# ESP32 register map
Vendor: ESPRESSIF SYSTEMS (SHANGHAI) CO., LTD.; Series: ESP32 Series; File version: 17
CPU: Xtensa LX6 r0p0, little endian, no MPU, FPU, 0 interrupt priority bits
Address unit: 32 bits
Registers are 32-bit, read-write, reset 0x0 unless marked. A register's access mark holds for its fields unless they carry their own. Offsets are from the block's base; [hi:lo] are bit positions; {n}, {i} and the like mark numbered series.

## I2C0 — I2C (Inter-Integrated Circuit) Controller 0
Base 0x3FF53000
Same registers: I2C1 0x3FF67000
0x00 SCL_LOW_PERIOD
  [13:0] SCL_LOW_PERIOD — This register is used to configure the low level width of SCL clock.
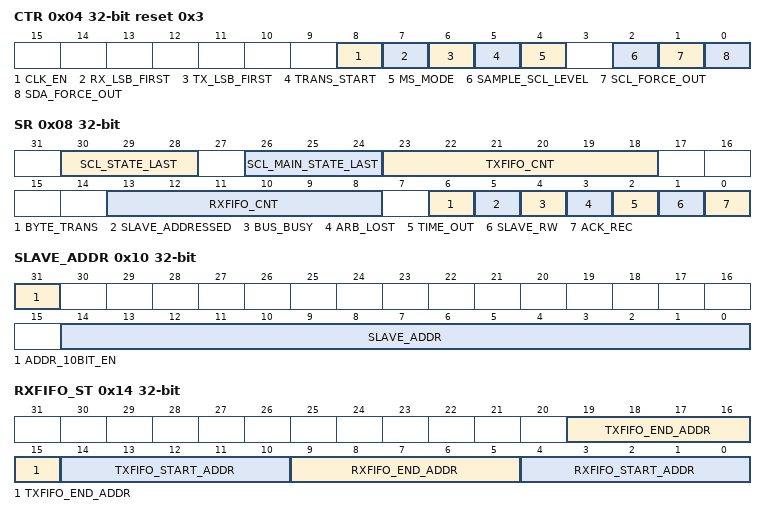
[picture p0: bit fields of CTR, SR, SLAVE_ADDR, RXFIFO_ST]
0x04 CTR reset 0x3
  [8] CLK_EN — This is the clock gating control bit for reading or writing registers.
  [7] RX_LSB_FIRST — This bit is used to control the storage mode for received datas. 1: receive data from most significant bit 0: receive data from least significant bit
  [6] TX_LSB_FIRST — This bit is used to control the sending mode for data need to be send. 1: receive data from most significant bit 0: receive data from least significant bit
  [5] TRANS_START — Set this bit to start sending data in txfifo.
  [4] MS_MODE — Set this bit to configure the module as i2c master clear this bit to configure the module as i2c slave.
  [2] SAMPLE_SCL_LEVEL — Set this bit to sample data in SCL low level. clear this bit to sample data in SCL high level.
  [1] SCL_FORCE_OUT — 1: normally ouput scl clock 0: exchange the function of scl_o and scl_oe (scl_o is the original internal output scl signal scl_oe is the enable bit for the internal output scl signal)
  [0] SDA_FORCE_OUT — 1: normally ouput sda data 0: exchange the function of sda_o and sda_oe (sda_o is the original internal output sda signal sda_oe is the enable bit for the internal output sda signal)
0x08 SR ro
  [30:28] SCL_STATE_LAST — This register stores the value of state machine to produce SCL. 3'h0: SCL_IDLE 3'h1:SCL_START 3'h2:SCL_LOW_EDGE 3'h3: SCL_LOW 3'h4:SCL_HIGH_EDGE 3'h5:SCL_HIGH 3'h6:SCL_STOP
  [26:24] SCL_MAIN_STATE_LAST — This register stores the value of state machine for i2c module. 3'h0: SCL_MAIN_IDLE 3'h1: SCL_ADDRESS_SHIFT 3'h2: SCL_ACK_ADDRESS 3'h3: SCL_RX_DATA 3'h4 SCL_TX_DATA 3'h5:SCL_SEND_ACK 3'h6:SCL_WAIT_ACK
  [23:18] TXFIFO_CNT — This register stores the amount of received data in ram.
  [13:8] RXFIFO_CNT — This register represent the amount of data need to send.
  [6] BYTE_TRANS — This register changes to high level when one byte is transferred.
  [5] SLAVE_ADDRESSED — when configured as i2c slave and the address send by master is equal to slave's address then this bit will be high level.
  [4] BUS_BUSY — 1:I2C bus is busy transferring data. 0:I2C bus is in idle state.
  [3] ARB_LOST — when I2C lost control of SDA line this register changes to high level.
  [2] TIME_OUT — when I2C takes more than time_out_reg clocks to receive a data then this register changes to high level.
  [1] SLAVE_RW — when in slave mode 1: master read slave 0: master write slave.
  [0] ACK_REC — This register stores the value of ACK bit.
0x0C TO
  [19:0] TIME_OUT — This register is used to configure the max clock number of receiving a data.
0x10 SLAVE_ADDR
  [31] ADDR_10BIT_EN — This register is used to enable slave 10bit address mode.
  [14:0] SLAVE_ADDR — when configured as i2c slave this register is used to configure slave's address.
0x14 RXFIFO_ST ro
  [19:15] TXFIFO_END_ADDR — This is the offset address of the last sending data as described in nonfifo_tx_thres register.
  [14:10] TXFIFO_START_ADDR — This is the offset address of the first sending data as described in nonfifo_tx_thres register.
  [9:5] RXFIFO_END_ADDR — This is the offset address of the first receiving data as described in nonfifo_rx_thres_register.
  [4:0] RXFIFO_START_ADDR — This is the offset address of the last receiving data as described in nonfifo_rx_thres_register.
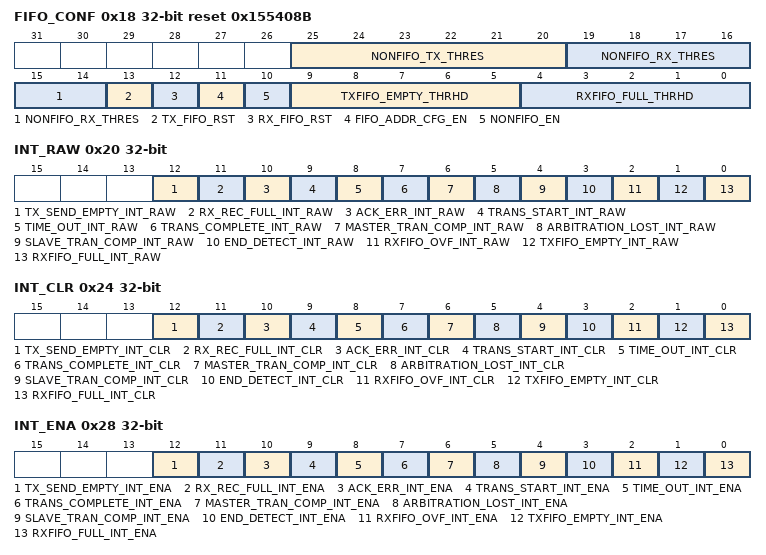
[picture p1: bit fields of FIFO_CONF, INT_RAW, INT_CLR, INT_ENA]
0x18 FIFO_CONF reset 0x155408B
  [25:20] NONFIFO_TX_THRES — when I2C sends more than nonfifo_tx_thres data it will produce tx_send_empty_int_raw interrupt and update the current offset address of the sending data.
  [19:14] NONFIFO_RX_THRES — when I2C receives more than nonfifo_rx_thres data it will produce rx_send_full_int_raw interrupt and update the current offset address of the receiving data.
  [13] TX_FIFO_RST — Set this bit to reset tx fifo when using apb fifo access.
  [12] RX_FIFO_RST — Set this bit to reset rx fifo when using apb fifo access.
  [11] FIFO_ADDR_CFG_EN — When this bit is set to 1 then the byte after address represent the offset address of I2C Slave's ram.
  [10] NONFIFO_EN — Set this bit to enble apb nonfifo access.
  [9:5] TXFIFO_EMPTY_THRHD — Config txfifo empty threhd value when using apb fifo access
  [4:0] RXFIFO_FULL_THRHD
0x1C DATA ro
  [7:0] FIFO_RDATA — The register represent the byte data read from rxfifo when use apb fifo access
0x20 INT_RAW ro
  [12] TX_SEND_EMPTY_INT_RAW — The raw interrupt status bit for tx_send_empty_int interrupt.when I2C sends more data than nonfifo_tx_thres it will produce tx_send_empty_int interrupt..
  [11] RX_REC_FULL_INT_RAW — The raw interrupt status bit for rx_rec_full_int interrupt. when I2C receives more data than nonfifo_rx_thres it will produce rx_rec_full_int interrupt.
  [10] ACK_ERR_INT_RAW — The raw interrupt status bit for ack_err_int interrupt. when I2C receives a wrong ACK bit it will produce ack_err_int interrupt..
  [9] TRANS_START_INT_RAW — The raw interrupt status bit for trans_start_int interrupt. when I2C sends the START bit it will produce trans_start_int interrupt.
  [8] TIME_OUT_INT_RAW — The raw interrupt status bit for time_out_int interrupt. when I2C takes a lot of time to receive a data it will produce time_out_int interrupt.
  [7] TRANS_COMPLETE_INT_RAW — The raw interrupt status bit for trans_complete_int interrupt. when I2C Master finished STOP command it will produce trans_complete_int interrupt.
  [6] MASTER_TRAN_COMP_INT_RAW — The raw interrupt status bit for master_tra_comp_int interrupt. when I2C Master sends or receives a byte it will produce master_tran_comp_int interrupt.
  [5] ARBITRATION_LOST_INT_RAW — The raw interrupt status bit for arbitration_lost_int interrupt.when I2C lost the usage right of I2C BUS it will produce arbitration_lost_int interrupt.
  [4] SLAVE_TRAN_COMP_INT_RAW — The raw interrupt status bit for slave_tran_comp_int interrupt. when I2C Slave detectsthe STOP bit it will produce slave_tran_comp_int interrupt.
  [3] END_DETECT_INT_RAW — The raw interrupt status bit for end_detect_int interrupt. when I2C deals with the END command it will produce end_detect_int interrupt.
  [2] RXFIFO_OVF_INT_RAW — The raw interrupt status bit for receiving data overflow when use apb fifo access.
  [1] TXFIFO_EMPTY_INT_RAW — The raw interrupt status bit for txfifo empty when use apb fifo access.
  [0] RXFIFO_FULL_INT_RAW — The raw interrupt status bit for rxfifo full when use apb fifo access.
0x24 INT_CLR wo
  [12] TX_SEND_EMPTY_INT_CLR — Set this bit to clear the tx_send_empty_int interrupt.
  [11] RX_REC_FULL_INT_CLR — Set this bit to clear the rx_rec_full_int interrupt.
  [10] ACK_ERR_INT_CLR — Set this bit to clear the ack_err_int interrupt.
  [9] TRANS_START_INT_CLR — Set this bit to clear the trans_start_int interrupt.
  [8] TIME_OUT_INT_CLR — Set this bit to clear the time_out_int interrupt.
  [7] TRANS_COMPLETE_INT_CLR — Set this bit to clear the trans_complete_int interrupt.
  [6] MASTER_TRAN_COMP_INT_CLR — Set this bit to clear the master_tran_comp interrupt.
  [5] ARBITRATION_LOST_INT_CLR — Set this bit to clear the arbitration_lost_int interrupt.
  [4] SLAVE_TRAN_COMP_INT_CLR — Set this bit to clear the slave_tran_comp_int interrupt.
  [3] END_DETECT_INT_CLR — Set this bit to clear the end_detect_int interrupt.
  [2] RXFIFO_OVF_INT_CLR — Set this bit to clear the rxfifo_ovf_int interrupt.
  [1] TXFIFO_EMPTY_INT_CLR — Set this bit to clear the txfifo_empty_int interrupt.
  [0] RXFIFO_FULL_INT_CLR — Set this bit to clear the rxfifo_full_int interrupt.
0x28 INT_ENA
  [12] TX_SEND_EMPTY_INT_ENA — The enable bit for tx_send_empty_int interrupt.
  [11] RX_REC_FULL_INT_ENA — The enable bit for rx_rec_full_int interrupt.
  [10] ACK_ERR_INT_ENA — The enable bit for ack_err_int interrupt.
  [9] TRANS_START_INT_ENA — The enable bit for trans_start_int interrupt.
  [8] TIME_OUT_INT_ENA — The enable bit for time_out_int interrupt.
  [7] TRANS_COMPLETE_INT_ENA — The enable bit for trans_complete_int interrupt.
  [6] MASTER_TRAN_COMP_INT_ENA — The enable bit for master_tran_comp_int interrupt.
  [5] ARBITRATION_LOST_INT_ENA — The enable bit for arbitration_lost_int interrupt.
  [4] SLAVE_TRAN_COMP_INT_ENA — The enable bit for slave_tran_comp_int interrupt.
  [3] END_DETECT_INT_ENA — The enable bit for end_detect_int interrupt.
  [2] RXFIFO_OVF_INT_ENA — The enable bit for rxfifo_ovf_int interrupt.
  [1] TXFIFO_EMPTY_INT_ENA — The enable bit for txfifo_empty_int interrupt.
  [0] RXFIFO_FULL_INT_ENA — The enable bit for rxfifo_full_int interrupt.
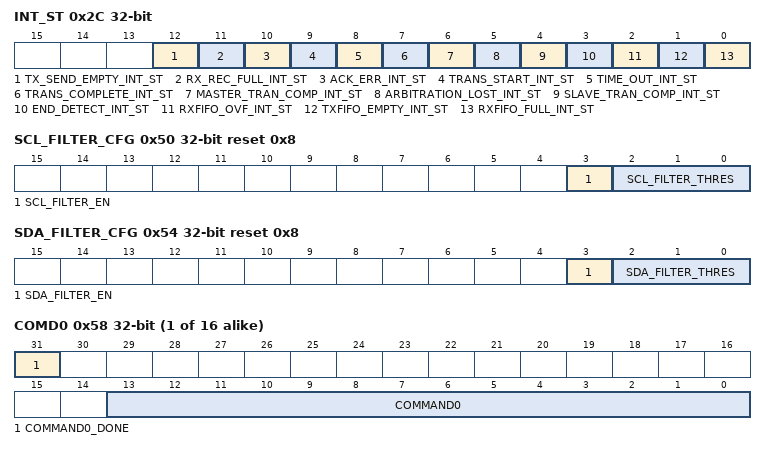
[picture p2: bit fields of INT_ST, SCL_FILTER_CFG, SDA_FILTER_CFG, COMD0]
0x2C INT_ST ro
  [12] TX_SEND_EMPTY_INT_ST — The masked interrupt status for tx_send_empty_int interrupt.
  [11] RX_REC_FULL_INT_ST — The masked interrupt status for rx_rec_full_int interrupt.
  [10] ACK_ERR_INT_ST — The masked interrupt status for ack_err_int interrupt.
  [9] TRANS_START_INT_ST — The masked interrupt status for trans_start_int interrupt.
  [8] TIME_OUT_INT_ST — The masked interrupt status for time_out_int interrupt.
  [7] TRANS_COMPLETE_INT_ST — The masked interrupt status for trans_complete_int interrupt.
  [6] MASTER_TRAN_COMP_INT_ST — The masked interrupt status for master_tran_comp_int interrupt.
  [5] ARBITRATION_LOST_INT_ST — The masked interrupt status for arbitration_lost_int interrupt.
  [4] SLAVE_TRAN_COMP_INT_ST — The masked interrupt status for slave_tran_comp_int interrupt.
  [3] END_DETECT_INT_ST — The masked interrupt status for end_detect_int interrupt.
  [2] RXFIFO_OVF_INT_ST — The masked interrupt status for rxfifo_ovf_int interrupt.
  [1] TXFIFO_EMPTY_INT_ST — The masked interrupt status for txfifo_empty_int interrupt.
  [0] RXFIFO_FULL_INT_ST — The masked interrupt status for rxfifo_full_int interrupt.
0x30 SDA_HOLD
  [9:0] TIME — This register is used to configure the clock num I2C used to hold the data after the negedge of SCL.
0x34 SDA_SAMPLE
  [9:0] TIME — This register is used to configure the clock num I2C used to sample data on SDA after the posedge of SCL
0x38 SCL_HIGH_PERIOD
  [13:0] SCL_HIGH_PERIOD — This register is used to configure the clock num during SCL is low level.
0x40 SCL_START_HOLD reset 0x8
  [9:0] TIME — This register is used to configure the clock num between the negedge of SDA and negedge of SCL for start mark.
0x44 SCL_RSTART_SETUP reset 0x8
  [9:0] TIME — This register is used to configure the clock num between the posedge of SCL and the negedge of SDA for restart mark.
0x48 SCL_STOP_HOLD
  [13:0] TIME — This register is used to configure the clock num after the STOP bit's posedge.
0x4C SCL_STOP_SETUP
  [9:0] TIME — This register is used to configure the clock num between the posedge of SCL and the posedge of SDA.
0x50 SCL_FILTER_CFG reset 0x8
  [3] SCL_FILTER_EN — This is the filter enable bit for SCL.
  [2:0] SCL_FILTER_THRES — When input SCL's pulse width is smaller than this register value I2C ignores this pulse.
0x54 SDA_FILTER_CFG reset 0x8
  [3] SDA_FILTER_EN — This is the filter enable bit for SDA.
  [2:0] SDA_FILTER_THRES — When input SCL's pulse width is smaller than this register value I2C ignores this pulse.
{0x58+4i} COMD{i} (i=0..15)
  [31] COMMAND{i}_DONE — When command{i} is done in I2C Master mode this bit changes to high level.
  [13:0] COMMAND{i} — This is the content of command{i}. It consists of three part. op_code is the command 0: RSTART 1: WRITE 2: READ 3: STOP . 4:END. Byte_num represent the number of data need to be send or data need to be received. ack_check_en ack_exp and ack value are used to control the ack bit.
0xF8 DATE reset 0x16042000
0x100 FIFO_START_ADDR access not given
